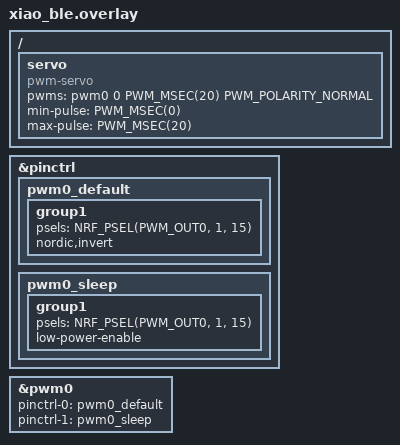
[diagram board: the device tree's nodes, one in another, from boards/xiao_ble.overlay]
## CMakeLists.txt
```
cmake_minimum_required(VERSION 3.20.0)
set(BOARD xiao_ble/nrf52840)
find_package(Zephyr REQUIRED HINTS $ENV{ZEPHYR_BASE})
project(anov)

target_sources(app PRIVATE
    src/main.c
    src/ble.c
    src/hw.c
)
```

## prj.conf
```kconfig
CONFIG_BT=y
CONFIG_LOG=y
CONFIG_BT_SMP=y
CONFIG_BT_PERIPHERAL=y
CONFIG_BT_DIS=y
CONFIG_BT_DIS_PNP=n
CONFIG_BT_BAS=y
CONFIG_BT_DEVICE_NAME="Anov"
CONFIG_BT_DEVICE_APPEARANCE=384

CONFIG_PWM=y
CONFIG_PWM_NRFX=y
CONFIG_PINCTRL=y

CONFIG_CBPRINTF_FP_SUPPORT=y
```

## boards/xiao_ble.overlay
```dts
/ {
    // this file informs Zephyr that a servo is connected to the board via PWM on
    // pwm0 (channel 1) with a 20 ms period, and it specifies the pulse width
    // range (700 µs to 2500 µs) that corresponds to the servo’s full range of motion.
    servo: servo {
        compatible = "pwm-servo";
        pwms = <&pwm0 0 PWM_MSEC(20) PWM_POLARITY_NORMAL>;
        min-pulse = <PWM_MSEC(0)>;
        max-pulse = <PWM_MSEC(20)>;
    };
};


&pinctrl {
    pwm0_default: pwm0_default {
        group1 {
			psels = <NRF_PSEL(PWM_OUT0, 1, 15)>;
			nordic,invert;
		};
    };
    pwm0_sleep: pwm0_sleep {
		group1 {
			psels = <NRF_PSEL(PWM_OUT0, 1, 15)>;
			low-power-enable;
		};
	};
};


&pwm0 {
    status = "okay";
    pinctrl-0 = <&pwm0_default>;
    pinctrl-1 = <&pwm0_sleep>;
	pinctrl-names = "default", "sleep";

};
```

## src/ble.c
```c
#include <zephyr/kernel.h>
#include <zephyr/bluetooth/bluetooth.h>
#include <zephyr/bluetooth/uuid.h>
#include <zephyr/bluetooth/gatt.h>
#include <zephyr/logging/log.h>
#include "hw.h"
#include "ble.h"

LOG_MODULE_REGISTER(ble, LOG_LEVEL_DBG);

/* Blueetooth connection callbacks */
static void on_connected(struct bt_conn *conn, uint8_t err)
{
    if (err) {
        LOG_ERR("Failed connection (error %d)", err);
        return;
    }

    char addr[BT_ADDR_LE_STR_LEN];
    bt_addr_le_to_str(bt_conn_get_dst(conn), addr, sizeof(addr));

    LOG_INF("Device connected: %s", addr);
}

static void on_disconnected(struct bt_conn *conn, uint8_t reason)
{
    char addr[BT_ADDR_LE_STR_LEN];
    bt_addr_le_to_str(bt_conn_get_dst(conn), addr, sizeof(addr));

    LOG_INF("Device disconnected: %s (reason: 0x%02x)", addr, reason);
}

static struct bt_conn_cb conn_callbacks = {
    .connected = on_connected,    
    .disconnected = on_disconnected, 
};

/* Random custom 128-bit UUIDs for both the service and command */
#define VIBRATOR_SERVICE_UUID_VAL \
    BT_UUID_128_ENCODE(0x771a69d3, 0xc9fc, 0x4674, 0x9bce, 0xca5c48f5ba55)

#define VIBRATOR_COMMAND_UUID_VAL \
    BT_UUID_128_ENCODE(0x73d978f7, 0x7dda, 0x4ef2, 0x8cb8, 0xc5e7ae10cc2a)

static struct bt_uuid_128 vibrator_service_uuid = BT_UUID_INIT_128(VIBRATOR_SERVICE_UUID_VAL);
static struct bt_uuid_128 vibrator_command_uuid = BT_UUID_INIT_128(VIBRATOR_COMMAND_UUID_VAL);

/* Command buffer */
#define MAX_CMD_LEN 64
static char vibrator_cmd[MAX_CMD_LEN + 1];

static ssize_t write_vibrator_cmd(struct bt_conn *conn,
                                  const struct bt_gatt_attr *attr,
                                  const void *buf, uint16_t len,
                                  uint16_t offset, uint8_t flags)
{
    if (offset != 0 || len == 0 || len > MAX_CMD_LEN) {
        return BT_GATT_ERR(BT_ATT_ERR_INVALID_OFFSET);
    }

    memset(vibrator_cmd, 0, sizeof(vibrator_cmd));
    memcpy(vibrator_cmd, buf, len);
    vibrator_control(vibrator_cmd);

    return len;
}

/* Bluetooth GATT service definition */
BT_GATT_SERVICE_DEFINE(vibrator_service,
    BT_GATT_PRIMARY_SERVICE(&vibrator_service_uuid),
    BT_GATT_CHARACTERISTIC(&vibrator_command_uuid.uuid,
                           BT_GATT_CHRC_WRITE_WITHOUT_RESP,
                           BT_GATT_PERM_WRITE,
                           NULL, write_vibrator_cmd, NULL),
);

/* Bluetooth initial advertisement data */
static const struct bt_data ad[] = {
    BT_DATA_BYTES(BT_DATA_FLAGS, (BT_LE_AD_GENERAL | BT_LE_AD_NO_BREDR)),
    BT_DATA_BYTES(BT_DATA_UUID128_ALL, VIBRATOR_SERVICE_UUID_VAL),
};

static const struct bt_data sd[] = {
    BT_DATA(BT_DATA_NAME_COMPLETE, CONFIG_BT_DEVICE_NAME, sizeof(CONFIG_BT_DEVICE_NAME) - 1),
};

static void bt_ready(int err)
{
    if (err) {
        LOG_ERR("Bluetooth init failed: %d", err);
        return;
    }

    bt_le_adv_start(BT_LE_ADV_CONN, ad, ARRAY_SIZE(ad), sd, ARRAY_SIZE(sd));
    LOG_INF("Advertising started");
}

void vibrator_ble_init(void)
{
    bt_conn_cb_register(&conn_callbacks);

    // Initialize Bluetooth
    int err = bt_enable(bt_ready);
    if (err) {
        LOG_ERR("Bluetooth enable failed: %d", err);
    }
}
```

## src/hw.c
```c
#include <zephyr/kernel.h>
#include <zephyr/logging/log.h>
#include <zephyr/device.h>
#include <zephyr/drivers/pwm.h>
#include "hw.h"

/* Load the servo device */
static const struct pwm_dt_spec servo = PWM_DT_SPEC_GET(DT_NODELABEL(servo));
static const uint32_t min_pulse = DT_PROP(DT_NODELABEL(servo), min_pulse);
static const uint32_t max_pulse = DT_PROP(DT_NODELABEL(servo), max_pulse);

LOG_MODULE_REGISTER(hw, LOG_LEVEL_DBG);

void vibrator_init(void)
{
    if (!pwm_is_ready_dt(&servo))
    {
        LOG_ERR("PWM device %s not ready", servo.dev->name);
        return;
    }

    // Initialize with 0% duty cycle
    pwm_set_pulse_dt(&servo, 0);
    LOG_INF("PWM initialized (range: %u-%u μs)", min_pulse, max_pulse);
}

// The current list of Toy Code device commands is as follows:

// D0 - Identify device & firmware version
// D1 - Identify TCode version
// D2 - List available axes and associated user range preferences
// DSTOP - Stop device

#define DEVICE_VERSION "1.0.0"
#define TCODE_VERSION "0.3"
void handle_device_cmd(const char *cmd)
{
    switch (cmd[1])
    {
    case '0':
        LOG_INF("Device: %s, Firmware: %s", CONFIG_BT_DEVICE_NAME, DEVICE_VERSION);
        break;
    case '1':
        LOG_INF("TCode version: %s", TCODE_VERSION);
        break;
    case '2':
        LOG_INF("Available axes: None");
        LOG_INF("User range preferences: 0-100");
        break;
    default:
        // DSTOP
        if (strcmp(cmd, "DSTOP") == 0)
        {
            LOG_INF("Stopping device");
            pwm_set_pulse_dt(&servo, 0);
        }
        else
        {
            LOG_WRN("Unknown device command: %s", cmd);
        }

        break;
    }
}

#define VIBRATION_CHANNEL '0'
#define BASE_CMD_LEN 2
void handle_vibration_cmd(const char *cmd, int len)
{

    // V + CHANNEL + digits (need at least 3 chars)
    if (strlen(cmd) <= BASE_CMD_LEN)
    {
        LOG_ERR("Invalid vibration command: %s", cmd);
        return;
    }
    if (cmd[1] != VIBRATION_CHANNEL)
    {
        LOG_ERR("Invalid vibration channel (we only have channel 0): %c", cmd[1]);
        return;
    }

    // Extract vibration intensity
    const char *mag_str = cmd + BASE_CMD_LEN;
    size_t mag_len = len - BASE_CMD_LEN;
    float magnitude = 0;
    int divisor = 1;
    // Magnitude is 0.DIGITS
    for (size_t i = 0; i < mag_len; i++)
    {
        if (mag_str[i] < '0' || mag_str[i] > '9')
        {
            LOG_INF("Invalid vibration intensity: %s", cmd);
            return;
        }
        magnitude = magnitude * 10 + (mag_str[i] - '0');
        divisor *= 10;
    }
    magnitude /= divisor;
    // Magnitude is now a float between 0 and 1

    //  Set PWM duty cycle based on magnitude
    uint32_t pulse = min_pulse + (max_pulse - min_pulse) * magnitude;

    pwm_set_pulse_dt(&servo, pulse);
    LOG_INF("Vibration channel %c set to %.2f%% (pulse: %u μs)", cmd[1], magnitude, pulse);
}

/* General vibrator command callback */
void vibrator_control(const char *cmd)
{
    int len = strlen(cmd);
    LOG_INF("Received command: %s", cmd);
    LOG_INF("with length: %d", len);
    LOG_INF("last char: %c", cmd[len - 1]);

    if (cmd == NULL || len == 0)
    {
        LOG_ERR("Received empty command: %s", cmd);
        return;
    }

    // If ends in newline remove it since official Toy Code spec requires it
    if (cmd[len - 1] == '\n')
    {
        len--;
    }
    switch (cmd[0])
    {
    case 'D':
        handle_device_cmd(cmd);
        break;
    case 'V':
        handle_vibration_cmd(cmd, len);
        break;
    default:
        break;
    }
}
```
